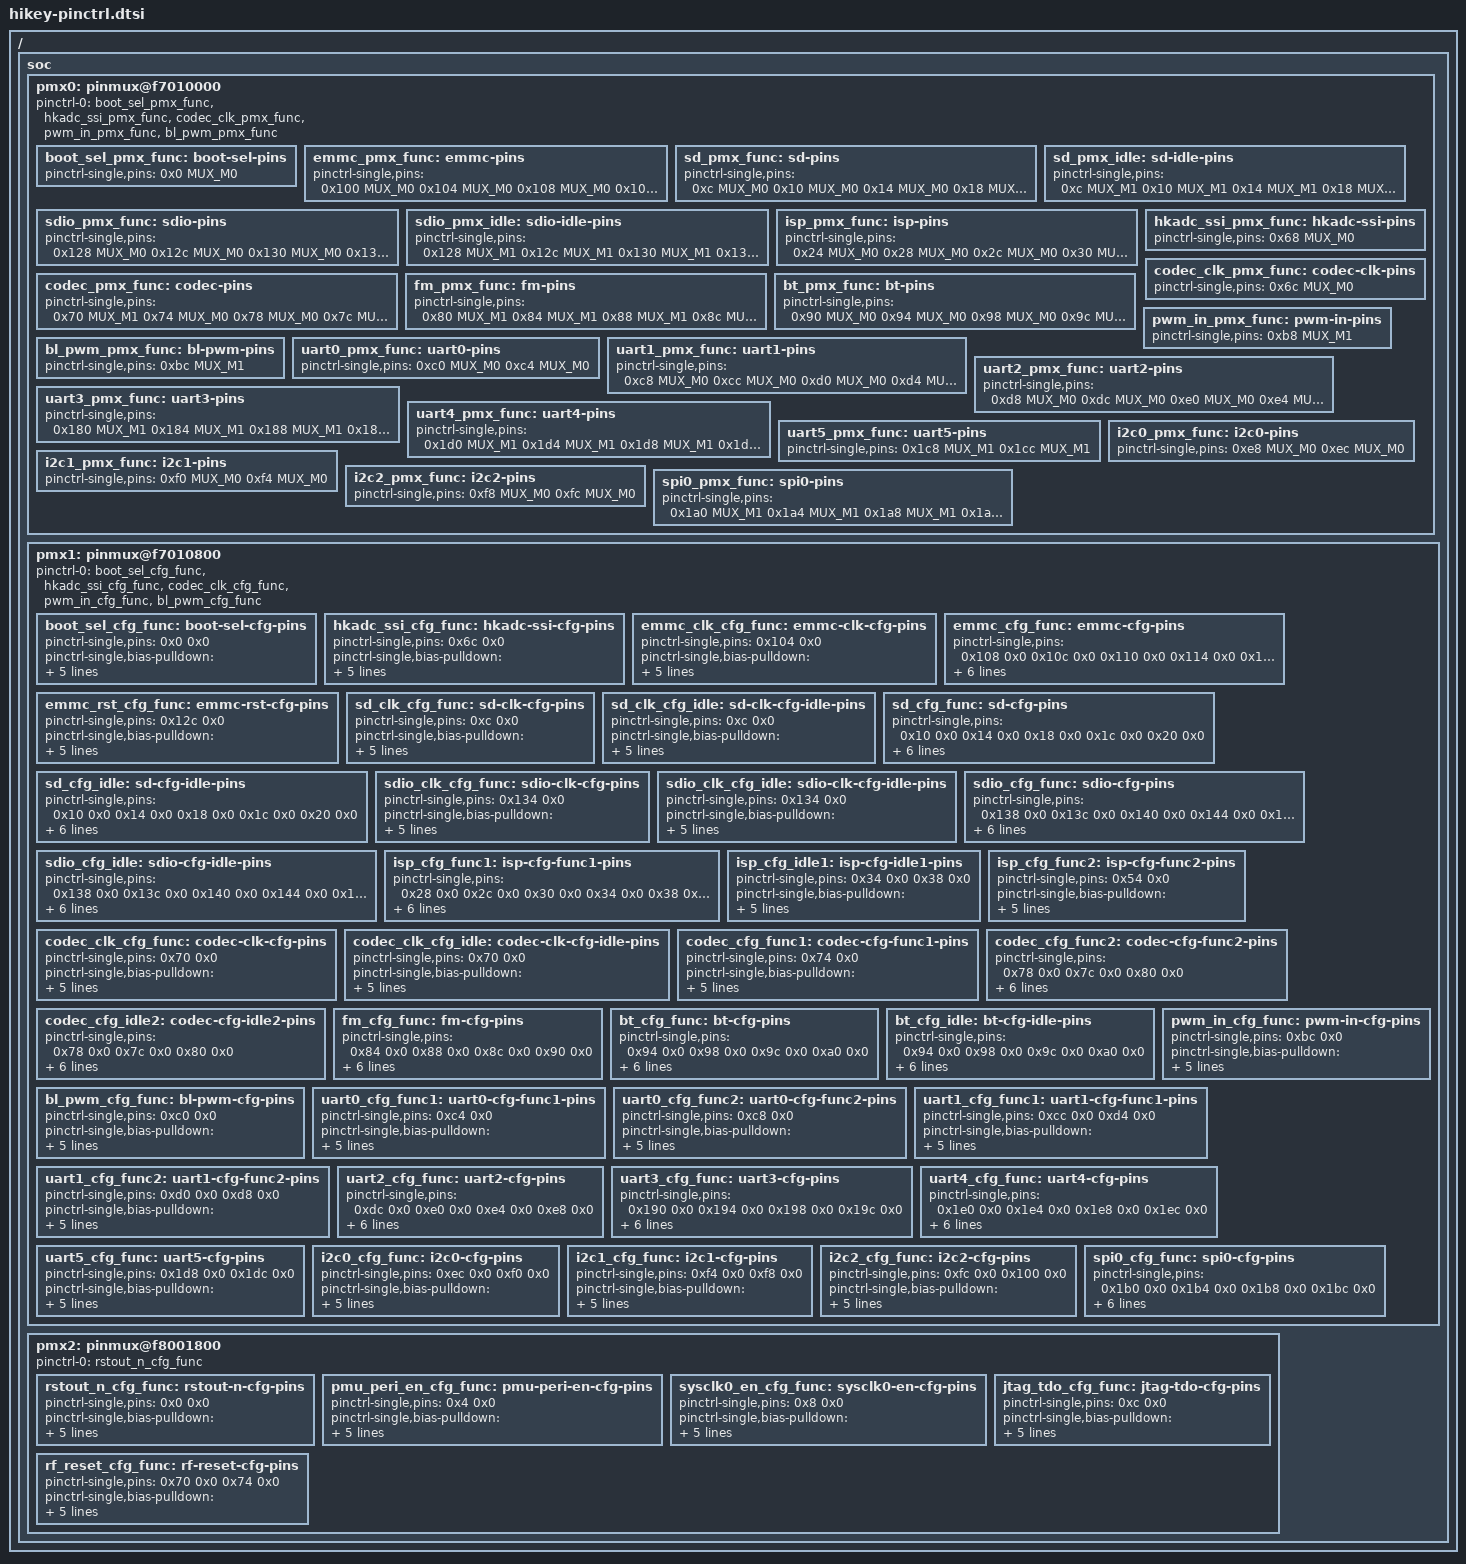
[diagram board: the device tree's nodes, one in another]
#include <dt-bindings/pinctrl/hisi.h>
/ {
	soc {
		pmx0: pinmux@f7010000 {
			pinctrl-names = "default";
			pinctrl-0 = <
				&boot_sel_pmx_func
				&hkadc_ssi_pmx_func
				&codec_clk_pmx_func
				&pwm_in_pmx_func
				&bl_pwm_pmx_func
				>;
			boot_sel_pmx_func: boot-sel-pins {
				pinctrl-single,pins = <
					0x0    MUX_M0	 
				>;
			};
			emmc_pmx_func: emmc-pins {
				pinctrl-single,pins = <
					0x100  MUX_M0	 
					0x104  MUX_M0	 
					0x108  MUX_M0	 
					0x10c  MUX_M0	 
					0x110  MUX_M0	 
					0x114  MUX_M0	 
					0x118  MUX_M0	 
					0x11c  MUX_M0	 
					0x120  MUX_M0	 
					0x124  MUX_M0	 
				>;
			};
			sd_pmx_func: sd-pins {
				pinctrl-single,pins = <
					0xc    MUX_M0	 
					0x10   MUX_M0	 
					0x14   MUX_M0	 
					0x18   MUX_M0	 
					0x1c   MUX_M0	 
					0x20   MUX_M0	 
				>;
			};
			sd_pmx_idle: sd-idle-pins {
				pinctrl-single,pins = <
					0xc    MUX_M1	 
					0x10   MUX_M1	 
					0x14   MUX_M1	 
					0x18   MUX_M1	 
					0x1c   MUX_M1	 
					0x20   MUX_M1	 
				>;
			};
			sdio_pmx_func: sdio-pins {
				pinctrl-single,pins = <
					0x128  MUX_M0	 
					0x12c  MUX_M0	 
					0x130  MUX_M0	 
					0x134  MUX_M0	 
					0x138  MUX_M0	 
					0x13c  MUX_M0	 
				>;
			};
			sdio_pmx_idle: sdio-idle-pins {
				pinctrl-single,pins = <
					0x128  MUX_M1	 
					0x12c  MUX_M1	 
					0x130  MUX_M1	 
					0x134  MUX_M1	 
					0x138  MUX_M1	 
					0x13c  MUX_M1	 
				>;
			};
			isp_pmx_func: isp-pins {
				pinctrl-single,pins = <
					0x24   MUX_M0	 
					0x28   MUX_M0	 
					0x2c   MUX_M0	 
					0x30   MUX_M1	 
					0x34   MUX_M1	 
					0x38   MUX_M1	 
					0x3c   MUX_M0	 
					0x40   MUX_M0	 
					0x44   MUX_M0	 
					0x48   MUX_M0	 
					0x4c   MUX_M1	 
					0x50   MUX_M1	 
					0x54   MUX_M0	 
					0x58   MUX_M0	 
					0x5c   MUX_M0	 
					0x60   MUX_M0	 
				>;
			};
			hkadc_ssi_pmx_func: hkadc-ssi-pins {
				pinctrl-single,pins = <
					0x68   MUX_M0	 
				>;
			};
			codec_clk_pmx_func: codec-clk-pins {
				pinctrl-single,pins = <
					0x6c   MUX_M0	 
				>;
			};
			codec_pmx_func: codec-pins {
				pinctrl-single,pins = <
					0x70   MUX_M1	 
					0x74   MUX_M0	 
					0x78   MUX_M0	 
					0x7c   MUX_M0	 
				>;
			};
			fm_pmx_func: fm-pins {
				pinctrl-single,pins = <
					0x80   MUX_M1	 
					0x84   MUX_M1	 
					0x88   MUX_M1	 
					0x8c   MUX_M1	 
				>;
			};
			bt_pmx_func: bt-pins {
				pinctrl-single,pins = <
					0x90   MUX_M0	 
					0x94   MUX_M0	 
					0x98   MUX_M0	 
					0x9c   MUX_M0	 
				>;
			};
			pwm_in_pmx_func: pwm-in-pins {
				pinctrl-single,pins = <
					0xb8   MUX_M1	 
				>;
			};
			bl_pwm_pmx_func: bl-pwm-pins {
				pinctrl-single,pins = <
					0xbc   MUX_M1	 
				>;
			};
			uart0_pmx_func: uart0-pins {
				pinctrl-single,pins = <
					0xc0   MUX_M0	 
					0xc4   MUX_M0	 
				>;
			};
			uart1_pmx_func: uart1-pins {
				pinctrl-single,pins = <
					0xc8   MUX_M0	 
					0xcc   MUX_M0	 
					0xd0   MUX_M0	 
					0xd4   MUX_M0	 
				>;
			};
			uart2_pmx_func: uart2-pins {
				pinctrl-single,pins = <
					0xd8   MUX_M0	 
					0xdc   MUX_M0	 
					0xe0   MUX_M0	 
					0xe4   MUX_M0	 
				>;
			};
			uart3_pmx_func: uart3-pins {
				pinctrl-single,pins = <
					0x180  MUX_M1	 
					0x184  MUX_M1	 
					0x188  MUX_M1	 
					0x18c  MUX_M1	 
				>;
			};
			uart4_pmx_func: uart4-pins {
				pinctrl-single,pins = <
					0x1d0  MUX_M1	 
					0x1d4  MUX_M1	 
					0x1d8  MUX_M1	 
					0x1dc  MUX_M1	 
				>;
			};
			uart5_pmx_func: uart5-pins {
				pinctrl-single,pins = <
					0x1c8  MUX_M1	 
					0x1cc  MUX_M1	 
				>;
			};
			i2c0_pmx_func: i2c0-pins {
				pinctrl-single,pins = <
					0xe8   MUX_M0	 
					0xec   MUX_M0	 
				>;
			};
			i2c1_pmx_func: i2c1-pins {
				pinctrl-single,pins = <
					0xf0   MUX_M0	 
					0xf4   MUX_M0	 
				>;
			};
			i2c2_pmx_func: i2c2-pins {
				pinctrl-single,pins = <
					0xf8   MUX_M0	 
					0xfc   MUX_M0	 
				>;
			};
			spi0_pmx_func: spi0-pins {
				pinctrl-single,pins = <
					0x1a0  MUX_M1    
					0x1a4  MUX_M1	 
					0x1a8  MUX_M1	 
					0x1ac  MUX_M1	 
				>;
			};
		};
		pmx1: pinmux@f7010800 {
			pinctrl-names = "default";
			pinctrl-0 = <
				&boot_sel_cfg_func
				&hkadc_ssi_cfg_func
				&codec_clk_cfg_func
				&pwm_in_cfg_func
				&bl_pwm_cfg_func
				>;
			boot_sel_cfg_func: boot-sel-cfg-pins {
				pinctrl-single,pins = <
					0x0    0x0	 
				>;
				pinctrl-single,bias-pulldown  = <PULL_DIS  PULL_DOWN PULL_DIS  PULL_DOWN>;
				pinctrl-single,bias-pullup    = <PULL_UP   PULL_UP   PULL_DIS  PULL_UP>;
				pinctrl-single,drive-strength = <DRIVE1_02MA DRIVE_MASK>;
			};
			hkadc_ssi_cfg_func: hkadc-ssi-cfg-pins {
				pinctrl-single,pins = <
					0x6c   0x0	 
				>;
				pinctrl-single,bias-pulldown  = <PULL_DIS  PULL_DOWN PULL_DIS  PULL_DOWN>;
				pinctrl-single,bias-pullup    = <PULL_DIS  PULL_UP   PULL_DIS  PULL_UP>;
				pinctrl-single,drive-strength = <DRIVE1_02MA DRIVE_MASK>;
			};
			emmc_clk_cfg_func: emmc-clk-cfg-pins {
				pinctrl-single,pins = <
					0x104  0x0	 
				>;
				pinctrl-single,bias-pulldown  = <PULL_DIS  PULL_DOWN PULL_DIS  PULL_DOWN>;
				pinctrl-single,bias-pullup    = <PULL_DIS  PULL_UP   PULL_DIS  PULL_UP>;
				pinctrl-single,drive-strength = <DRIVE1_08MA DRIVE_MASK>;
			};
			emmc_cfg_func: emmc-cfg-pins {
				pinctrl-single,pins = <
					0x108  0x0	 
					0x10c  0x0	 
					0x110  0x0	 
					0x114  0x0	 
					0x118  0x0	 
					0x11c  0x0	 
					0x120  0x0	 
					0x124  0x0	 
					0x128  0x0	 
				>;
				pinctrl-single,bias-pulldown  = <PULL_DIS  PULL_DOWN PULL_DIS  PULL_DOWN>;
				pinctrl-single,bias-pullup    = <PULL_UP   PULL_UP   PULL_DIS  PULL_UP>;
				pinctrl-single,drive-strength = <DRIVE1_04MA DRIVE_MASK>;
			};
			emmc_rst_cfg_func: emmc-rst-cfg-pins {
				pinctrl-single,pins = <
					0x12c  0x0	 
				>;
				pinctrl-single,bias-pulldown  = <PULL_DIS  PULL_DOWN PULL_DIS  PULL_DOWN>;
				pinctrl-single,bias-pullup    = <PULL_DIS  PULL_UP   PULL_DIS  PULL_UP>;
				pinctrl-single,drive-strength = <DRIVE1_04MA DRIVE_MASK>;
			};
			sd_clk_cfg_func: sd-clk-cfg-pins {
				pinctrl-single,pins = <
					0xc    0x0	 
				>;
				pinctrl-single,bias-pulldown  = <PULL_DIS  PULL_DOWN PULL_DIS  PULL_DOWN>;
				pinctrl-single,bias-pullup    = <PULL_DIS  PULL_UP   PULL_DIS  PULL_UP>;
				pinctrl-single,drive-strength = <DRIVE1_10MA DRIVE_MASK>;
			};
			sd_clk_cfg_idle: sd-clk-cfg-idle-pins {
				pinctrl-single,pins = <
					0xc    0x0	 
				>;
				pinctrl-single,bias-pulldown  = <PULL_DOWN PULL_DOWN PULL_DIS  PULL_DOWN>;
				pinctrl-single,bias-pullup    = <PULL_DIS  PULL_UP   PULL_DIS  PULL_UP>;
				pinctrl-single,drive-strength = <DRIVE1_02MA DRIVE_MASK>;
			};
			sd_cfg_func: sd-cfg-pins {
				pinctrl-single,pins = <
					0x10   0x0	 
					0x14   0x0	 
					0x18   0x0	 
					0x1c   0x0	 
					0x20   0x0	 
				>;
				pinctrl-single,bias-pulldown  = <PULL_DIS  PULL_DOWN PULL_DIS  PULL_DOWN>;
				pinctrl-single,bias-pullup    = <PULL_DIS  PULL_UP   PULL_DIS  PULL_UP>;
				pinctrl-single,drive-strength = <DRIVE1_08MA DRIVE_MASK>;
			};
			sd_cfg_idle: sd-cfg-idle-pins {
				pinctrl-single,pins = <
					0x10   0x0	 
					0x14   0x0	 
					0x18   0x0	 
					0x1c   0x0	 
					0x20   0x0	 
				>;
				pinctrl-single,bias-pulldown  = <PULL_DOWN PULL_DOWN PULL_DIS  PULL_DOWN>;
				pinctrl-single,bias-pullup    = <PULL_DIS  PULL_UP   PULL_DIS  PULL_UP>;
				pinctrl-single,drive-strength = <DRIVE1_02MA DRIVE_MASK>;
			};
			sdio_clk_cfg_func: sdio-clk-cfg-pins {
				pinctrl-single,pins = <
					0x134  0x0	 
				>;
				pinctrl-single,bias-pulldown  = <PULL_DIS  PULL_DOWN PULL_DIS  PULL_DOWN>;
				pinctrl-single,bias-pullup    = <PULL_DIS  PULL_UP   PULL_DIS  PULL_UP>;
				pinctrl-single,drive-strength = <DRIVE1_08MA DRIVE_MASK>;
			};
			sdio_clk_cfg_idle: sdio-clk-cfg-idle-pins {
				pinctrl-single,pins = <
					0x134  0x0	 
				>;
				pinctrl-single,bias-pulldown  = <PULL_DOWN PULL_DOWN PULL_DIS  PULL_DOWN>;
				pinctrl-single,bias-pullup    = <PULL_DIS  PULL_UP   PULL_DIS  PULL_UP>;
				pinctrl-single,drive-strength = <DRIVE1_02MA DRIVE_MASK>;
			};
			sdio_cfg_func: sdio-cfg-pins {
				pinctrl-single,pins = <
					0x138  0x0	 
					0x13c  0x0	 
					0x140  0x0	 
					0x144  0x0	 
					0x148  0x0	 
				>;
				pinctrl-single,bias-pulldown  = <PULL_DIS  PULL_DOWN PULL_DIS  PULL_DOWN>;
				pinctrl-single,bias-pullup    = <PULL_UP   PULL_UP   PULL_DIS  PULL_UP>;
				pinctrl-single,drive-strength = <DRIVE1_04MA DRIVE_MASK>;
			};
			sdio_cfg_idle: sdio-cfg-idle-pins {
				pinctrl-single,pins = <
					0x138  0x0	 
					0x13c  0x0	 
					0x140  0x0	 
					0x144  0x0	 
					0x148  0x0	 
				>;
				pinctrl-single,bias-pulldown  = <PULL_DIS  PULL_DOWN PULL_DIS  PULL_DOWN>;
				pinctrl-single,bias-pullup    = <PULL_UP   PULL_UP   PULL_DIS  PULL_UP>;
				pinctrl-single,drive-strength = <DRIVE1_02MA DRIVE_MASK>;
			};
			isp_cfg_func1: isp-cfg-func1-pins {
				pinctrl-single,pins = <
					0x28   0x0	 
					0x2c   0x0	 
					0x30   0x0	 
					0x34   0x0	 
					0x38   0x0	 
					0x3c   0x0	 
					0x40   0x0	 
					0x44   0x0	 
					0x48   0x0	 
					0x4c   0x0	 
					0x50   0x0	 
					0x58   0x0	 
					0x5c   0x0	 
					0x60   0x0	 
					0x64   0x0	 
				>;
				pinctrl-single,bias-pulldown  = <PULL_DIS  PULL_DOWN PULL_DIS  PULL_DOWN>;
				pinctrl-single,bias-pullup    = <PULL_DIS  PULL_UP   PULL_DIS  PULL_UP>;
				pinctrl-single,drive-strength = <DRIVE1_02MA DRIVE_MASK>;
			};
			isp_cfg_idle1: isp-cfg-idle1-pins {
				pinctrl-single,pins = <
					0x34   0x0	 
					0x38   0x0	 
				>;
				pinctrl-single,bias-pulldown  = <PULL_DOWN PULL_DOWN PULL_DIS  PULL_DOWN>;
				pinctrl-single,bias-pullup    = <PULL_DIS  PULL_UP   PULL_DIS  PULL_UP>;
				pinctrl-single,drive-strength = <DRIVE1_02MA DRIVE_MASK>;
			};
			isp_cfg_func2: isp-cfg-func2-pins {
				pinctrl-single,pins = <
					0x54   0x0	 
				>;
				pinctrl-single,bias-pulldown  = <PULL_DOWN PULL_DOWN PULL_DIS  PULL_DOWN>;
				pinctrl-single,bias-pullup    = <PULL_DIS  PULL_UP   PULL_DIS  PULL_UP>;
				pinctrl-single,drive-strength = <DRIVE1_02MA DRIVE_MASK>;
			};
			codec_clk_cfg_func: codec-clk-cfg-pins {
				pinctrl-single,pins = <
					0x70   0x0	 
				>;
				pinctrl-single,bias-pulldown  = <PULL_DIS  PULL_DOWN PULL_DIS  PULL_DOWN>;
				pinctrl-single,bias-pullup    = <PULL_DIS  PULL_UP   PULL_DIS  PULL_UP>;
				pinctrl-single,drive-strength = <DRIVE1_04MA DRIVE_MASK>;
			};
			codec_clk_cfg_idle: codec-clk-cfg-idle-pins {
				pinctrl-single,pins = <
					0x70   0x0	 
				>;
				pinctrl-single,bias-pulldown  = <PULL_DIS  PULL_DOWN PULL_DIS  PULL_DOWN>;
				pinctrl-single,bias-pullup    = <PULL_DIS  PULL_UP   PULL_DIS  PULL_UP>;
				pinctrl-single,drive-strength = <DRIVE1_02MA DRIVE_MASK>;
			};
			codec_cfg_func1: codec-cfg-func1-pins {
				pinctrl-single,pins = <
					0x74   0x0	 
				>;
				pinctrl-single,bias-pulldown  = <PULL_DOWN PULL_DOWN PULL_DIS  PULL_DOWN>;
				pinctrl-single,bias-pullup    = <PULL_DIS  PULL_UP   PULL_DIS  PULL_UP>;
				pinctrl-single,drive-strength = <DRIVE1_02MA DRIVE_MASK>;
			};
			codec_cfg_func2: codec-cfg-func2-pins {
				pinctrl-single,pins = <
					0x78   0x0	 
					0x7c   0x0	 
					0x80   0x0	 
				>;
				pinctrl-single,bias-pulldown  = <PULL_DIS  PULL_DOWN PULL_DIS  PULL_DOWN>;
				pinctrl-single,bias-pullup    = <PULL_DIS  PULL_UP   PULL_DIS  PULL_UP>;
				pinctrl-single,drive-strength = <DRIVE1_04MA DRIVE_MASK>;
			};
			codec_cfg_idle2: codec-cfg-idle2-pins {
				pinctrl-single,pins = <
					0x78   0x0	 
					0x7c   0x0	 
					0x80   0x0	 
				>;
				pinctrl-single,bias-pulldown  = <PULL_DIS  PULL_DOWN PULL_DIS  PULL_DOWN>;
				pinctrl-single,bias-pullup    = <PULL_DIS  PULL_UP   PULL_DIS  PULL_UP>;
				pinctrl-single,drive-strength = <DRIVE1_02MA DRIVE_MASK>;
			};
			fm_cfg_func: fm-cfg-pins {
				pinctrl-single,pins = <
					0x84   0x0	 
					0x88   0x0	 
					0x8c   0x0	 
					0x90   0x0	 
				>;
				pinctrl-single,bias-pulldown  = <PULL_DOWN PULL_DOWN PULL_DIS  PULL_DOWN>;
				pinctrl-single,bias-pullup    = <PULL_DIS  PULL_UP   PULL_DIS  PULL_UP>;
				pinctrl-single,drive-strength = <DRIVE1_02MA DRIVE_MASK>;
			};
			bt_cfg_func: bt-cfg-pins {
				pinctrl-single,pins = <
					0x94   0x0	 
					0x98   0x0	 
					0x9c   0x0	 
					0xa0   0x0	 
				>;
				pinctrl-single,bias-pulldown  = <PULL_DIS  PULL_DOWN PULL_DIS  PULL_DOWN>;
				pinctrl-single,bias-pullup    = <PULL_DIS  PULL_UP   PULL_DIS  PULL_UP>;
				pinctrl-single,drive-strength = <DRIVE1_02MA DRIVE_MASK>;
			};
			bt_cfg_idle: bt-cfg-idle-pins {
				pinctrl-single,pins = <
					0x94   0x0	 
					0x98   0x0	 
					0x9c   0x0	 
					0xa0   0x0	 
				>;
				pinctrl-single,bias-pulldown  = <PULL_DOWN PULL_DOWN PULL_DIS  PULL_DOWN>;
				pinctrl-single,bias-pullup    = <PULL_DIS  PULL_UP   PULL_DIS  PULL_UP>;
				pinctrl-single,drive-strength = <DRIVE1_02MA DRIVE_MASK>;
			};
			pwm_in_cfg_func: pwm-in-cfg-pins {
				pinctrl-single,pins = <
					0xbc   0x0	 
				>;
				pinctrl-single,bias-pulldown  = <PULL_DOWN PULL_DOWN PULL_DIS  PULL_DOWN>;
				pinctrl-single,bias-pullup    = <PULL_DIS  PULL_UP   PULL_DIS  PULL_UP>;
				pinctrl-single,drive-strength = <DRIVE1_02MA DRIVE_MASK>;
			};
			bl_pwm_cfg_func: bl-pwm-cfg-pins {
				pinctrl-single,pins = <
					0xc0   0x0	 
				>;
				pinctrl-single,bias-pulldown  = <PULL_DOWN PULL_DOWN PULL_DIS  PULL_DOWN>;
				pinctrl-single,bias-pullup    = <PULL_DIS  PULL_UP   PULL_DIS  PULL_UP>;
				pinctrl-single,drive-strength = <DRIVE1_02MA DRIVE_MASK>;
			};
			uart0_cfg_func1: uart0-cfg-func1-pins {
				pinctrl-single,pins = <
					0xc4   0x0	 
				>;
				pinctrl-single,bias-pulldown  = <PULL_DIS  PULL_DOWN PULL_DIS  PULL_DOWN>;
				pinctrl-single,bias-pullup    = <PULL_UP   PULL_UP   PULL_DIS  PULL_UP>;
				pinctrl-single,drive-strength = <DRIVE1_02MA DRIVE_MASK>;
			};
			uart0_cfg_func2: uart0-cfg-func2-pins {
				pinctrl-single,pins = <
					0xc8   0x0	 
				>;
				pinctrl-single,bias-pulldown  = <PULL_DIS  PULL_DOWN PULL_DIS  PULL_DOWN>;
				pinctrl-single,bias-pullup    = <PULL_DIS  PULL_UP   PULL_DIS  PULL_UP>;
				pinctrl-single,drive-strength = <DRIVE1_04MA DRIVE_MASK>;
			};
			uart1_cfg_func1: uart1-cfg-func1-pins {
				pinctrl-single,pins = <
					0xcc   0x0	 
					0xd4   0x0	 
				>;
				pinctrl-single,bias-pulldown  = <PULL_DIS  PULL_DOWN PULL_DIS  PULL_DOWN>;
				pinctrl-single,bias-pullup    = <PULL_UP   PULL_UP   PULL_DIS  PULL_UP>;
				pinctrl-single,drive-strength = <DRIVE1_02MA DRIVE_MASK>;
			};
			uart1_cfg_func2: uart1-cfg-func2-pins {
				pinctrl-single,pins = <
					0xd0   0x0	 
					0xd8   0x0	 
				>;
				pinctrl-single,bias-pulldown  = <PULL_DIS  PULL_DOWN PULL_DIS  PULL_DOWN>;
				pinctrl-single,bias-pullup    = <PULL_DIS  PULL_UP   PULL_DIS  PULL_UP>;
				pinctrl-single,drive-strength = <DRIVE1_02MA DRIVE_MASK>;
			};
			uart2_cfg_func: uart2-cfg-pins {
				pinctrl-single,pins = <
					0xdc   0x0	 
					0xe0   0x0	 
					0xe4   0x0	 
					0xe8   0x0	 
				>;
				pinctrl-single,bias-pulldown  = <PULL_DIS  PULL_DOWN PULL_DIS  PULL_DOWN>;
				pinctrl-single,bias-pullup    = <PULL_DIS  PULL_UP   PULL_DIS  PULL_UP>;
				pinctrl-single,drive-strength = <DRIVE1_02MA DRIVE_MASK>;
			};
			uart3_cfg_func: uart3-cfg-pins {
				pinctrl-single,pins = <
					0x190  0x0	 
					0x194  0x0	 
					0x198  0x0	 
					0x19c  0x0	 
				>;
				pinctrl-single,bias-pulldown  = <PULL_DOWN PULL_DOWN PULL_DIS  PULL_DOWN>;
				pinctrl-single,bias-pullup    = <PULL_DIS  PULL_UP   PULL_DIS  PULL_UP>;
				pinctrl-single,drive-strength = <DRIVE1_02MA DRIVE_MASK>;
			};
			uart4_cfg_func: uart4-cfg-pins {
				pinctrl-single,pins = <
					0x1e0  0x0	 
					0x1e4  0x0	 
					0x1e8  0x0	 
					0x1ec  0x0	 
				>;
				pinctrl-single,bias-pulldown  = <PULL_DOWN PULL_DOWN PULL_DIS  PULL_DOWN>;
				pinctrl-single,bias-pullup    = <PULL_DIS  PULL_UP   PULL_DIS  PULL_UP>;
				pinctrl-single,drive-strength = <DRIVE1_02MA DRIVE_MASK>;
			};
			uart5_cfg_func: uart5-cfg-pins {
				pinctrl-single,pins = <
					0x1d8  0x0	 
					0x1dc  0x0	 
				>;
				pinctrl-single,bias-pulldown  = <PULL_DOWN PULL_DOWN PULL_DIS  PULL_DOWN>;
				pinctrl-single,bias-pullup    = <PULL_DIS  PULL_UP   PULL_DIS  PULL_UP>;
				pinctrl-single,drive-strength = <DRIVE1_02MA DRIVE_MASK>;
			};
			i2c0_cfg_func: i2c0-cfg-pins {
				pinctrl-single,pins = <
					0xec   0x0	 
					0xf0   0x0	 
				>;
				pinctrl-single,bias-pulldown  = <PULL_DIS  PULL_DOWN PULL_DIS  PULL_DOWN>;
				pinctrl-single,bias-pullup    = <PULL_DIS  PULL_UP   PULL_DIS  PULL_UP>;
				pinctrl-single,drive-strength = <DRIVE1_02MA DRIVE_MASK>;
			};
			i2c1_cfg_func: i2c1-cfg-pins {
				pinctrl-single,pins = <
					0xf4   0x0	 
					0xf8   0x0	 
				>;
				pinctrl-single,bias-pulldown  = <PULL_DIS  PULL_DOWN PULL_DIS  PULL_DOWN>;
				pinctrl-single,bias-pullup    = <PULL_DIS  PULL_UP   PULL_DIS  PULL_UP>;
				pinctrl-single,drive-strength = <DRIVE1_02MA DRIVE_MASK>;
			};
			i2c2_cfg_func: i2c2-cfg-pins {
				pinctrl-single,pins = <
					0xfc   0x0	 
					0x100  0x0	 
				>;
				pinctrl-single,bias-pulldown  = <PULL_DIS  PULL_DOWN PULL_DIS  PULL_DOWN>;
				pinctrl-single,bias-pullup    = <PULL_DIS  PULL_UP   PULL_DIS  PULL_UP>;
				pinctrl-single,drive-strength = <DRIVE1_02MA DRIVE_MASK>;
			};
			spi0_cfg_func: spi0-cfg-pins {
				pinctrl-single,pins = <
					0x1b0  0x0	 
					0x1b4  0x0	 
					0x1b8  0x0	 
					0x1bc  0x0	 
				>;
				pinctrl-single,bias-pulldown  = <PULL_DIS  PULL_DOWN PULL_DIS PULL_DOWN>;
				pinctrl-single,bias-pullup    = <PULL_DIS  PULL_UP   PULL_DIS PULL_UP>;
				pinctrl-single,drive-strength = <DRIVE1_02MA DRIVE_MASK>;
			};
		};
		pmx2: pinmux@f8001800 {
			pinctrl-names = "default";
			pinctrl-0 = <
				&rstout_n_cfg_func
				>;
			rstout_n_cfg_func: rstout-n-cfg-pins {
				pinctrl-single,pins = <
					0x0    0x0	 
				>;
				pinctrl-single,bias-pulldown  = <PULL_DIS  PULL_DOWN PULL_DIS  PULL_DOWN>;
				pinctrl-single,bias-pullup    = <PULL_DIS  PULL_UP   PULL_DIS  PULL_UP>;
				pinctrl-single,drive-strength = <DRIVE1_02MA DRIVE_MASK>;
			};
			pmu_peri_en_cfg_func: pmu-peri-en-cfg-pins {
				pinctrl-single,pins = <
					0x4    0x0	 
				>;
				pinctrl-single,bias-pulldown  = <PULL_DIS  PULL_DOWN PULL_DIS  PULL_DOWN>;
				pinctrl-single,bias-pullup    = <PULL_DIS  PULL_UP   PULL_DIS  PULL_UP>;
				pinctrl-single,drive-strength = <DRIVE1_02MA DRIVE_MASK>;
			};
			sysclk0_en_cfg_func: sysclk0-en-cfg-pins {
				pinctrl-single,pins = <
					0x8    0x0	 
				>;
				pinctrl-single,bias-pulldown  = <PULL_DIS  PULL_DOWN PULL_DIS  PULL_DOWN>;
				pinctrl-single,bias-pullup    = <PULL_DIS  PULL_UP   PULL_DIS  PULL_UP>;
				pinctrl-single,drive-strength = <DRIVE1_02MA DRIVE_MASK>;
			};
			jtag_tdo_cfg_func: jtag-tdo-cfg-pins {
				pinctrl-single,pins = <
					0xc    0x0	 
				>;
				pinctrl-single,bias-pulldown  = <PULL_DIS  PULL_DOWN PULL_DIS  PULL_DOWN>;
				pinctrl-single,bias-pullup    = <PULL_DIS  PULL_UP   PULL_DIS  PULL_UP>;
				pinctrl-single,drive-strength = <DRIVE1_08MA DRIVE_MASK>;
			};
			rf_reset_cfg_func: rf-reset-cfg-pins {
				pinctrl-single,pins = <
					0x70   0x0	 
					0x74   0x0	 
				>;
				pinctrl-single,bias-pulldown  = <PULL_DIS  PULL_DOWN PULL_DIS  PULL_DOWN>;
				pinctrl-single,bias-pullup    = <PULL_DIS  PULL_UP   PULL_DIS  PULL_UP>;
				pinctrl-single,drive-strength = <DRIVE1_02MA DRIVE_MASK>;
			};
		};
	};
};
